# YTM32B1ME1 register map
Vendor: YTMicro; File version: 1.0
CPU: CM33 r0p4, little endian, MPU, FPU, 2 interrupt priority bits
Registers are 32-bit, read-write, reset 0x0 unless marked. A register's access mark holds for its fields unless they carry their own. Offsets are from the block's base; [hi:lo] are bit positions; {n}, {i} and the like mark numbered series; 'fields as' and 'values as' point back to an identical list; <NAME> marks a mode.

## SENT0 — Single Edge Nibble Transmission
Base 0x40160000; register names take the prefix SENT0_
0x00 CTRL
  [0] EN — Sent module enable control.
    0=Disabled; 1=Enabled
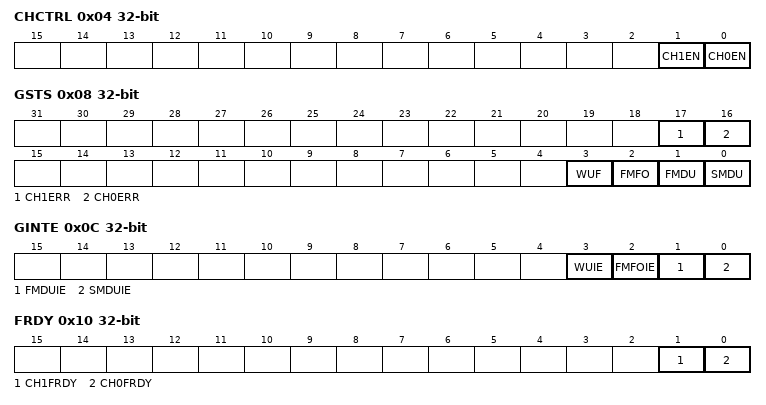
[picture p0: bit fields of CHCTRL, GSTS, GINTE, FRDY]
0x04 CHCTRL
  [1] CH1EN — Sent channel 1 enable control.
    0=Disabled; 1=Enabled
  [0] CH0EN — Sent channel 0 enable control.
    0=Disabled; 1=Enabled
0x08 GSTS
  [17] CH1ERR ro — Indicate channel 1 receive error status.
    0=No error detected; 1=Any error detected on channel 1
  [16] CH0ERR ro — Indicate channel 0 receive error status.
    0=No error detected; 1=Any error detected on channel 0
  [3] WUF — Indicate received valid data from PAD. This flag can be used to wake up chip from low power mode. Write 1 to clear this bit.
    0=No valid input was detected; 1=Valid input was detected
  [2] FMFO — Indicate fast message is received on any channel when FIFO is full. This bit is valid only when FIFO is enabled. Write 1 to clear this bit.
    0=No overflow; 1=Overflow occurred
  [1] FMDU — Indicate read when Fast Message DMA buffer or FIFO is empty. Write 1 to clear this bit.
    0=No underflow; 1=Underflow occurred
  [0] SMDU — Indicate read when Slow Serial Message DMA buffer is empty. Write 1 to clear this bit.
    0=No underflow; 1=Underflow occurred
0x0C GINTE
  [all] fields
    0=Disabled; 1=Enabled
  [3] WUIE — Wake-up interrupt enable control.
  [2] FMFOIE — Fast Message FIFO overflow interrupt enable control.
  [1] FMDUIE — Fast Message DMA buffer or FIFO underflow interrupt enable control.
  [0] SMDUIE — Slow Serial Message DMA buffer underflow interrupt enable control.
0x10 FRDY
  [1] CH1FRDY — Indicate channel 1 Fast Message receive ready.
    0=No Fast Message is available to be read out; 1=Fast Message is available to be read out
  [0] CH0FRDY — Indicate channel 0 Fast Message receive ready.
    values as CH1FRDY
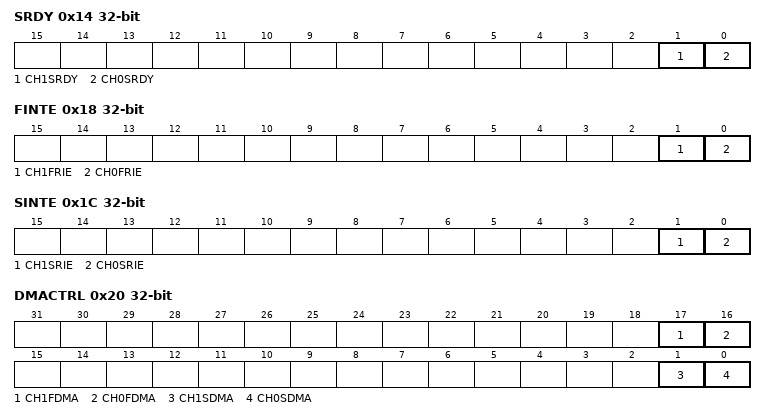
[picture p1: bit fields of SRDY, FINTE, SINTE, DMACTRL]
0x14 SRDY
  [1] CH1SRDY — Indicate channel 1 Slow Serial Message receive ready.
    0=No Slow Serial Message is available to be read out; 1=Slow Serial Message is available to be read out
  [0] CH0SRDY — Indicate channel 0 Slow Serial Message receive ready.
    values as CH1SRDY
0x18 FINTE
  [1] CH1FRIE — Channel 1 Fast Message ready interrupt enable control.
    0=Disabled; 1=Enable
  [0] CH0FRIE — Channel 0 Fast Message ready interrupt enable control.
    0=Disabled; 1=Enable
0x1C SINTE
  [1] CH1SRIE — Channel 1 Slow Serial Message ready interrupt enable control.
    0=Disabled; 1=Enabled
  [0] CH0SRIE — Channel 0 Slow Serial Message ready interrupt enable control.
    0=Disabled; 1=Enabled
0x20 DMACTRL
  [17] CH1FDMA — DMA enable control for Fast Message on channel 1.
    0=DMA for Fast Message is disabled; 1=DMA for Fast Message is enabled
  [16] CH0FDMA — DMA enable control for Fast Message on channel 0.
    values as CH1FDMA
  [1] CH1SDMA — DMA enable control for Slow Serial Message on channel 1.
    0=DMA for Slow Serial Message is disabled; 1=DMA for Slow Serial Message is enabled
  [0] CH0SDMA — DMA enable control for Slow Serial Message on channel 0.
    values as CH1SDMA
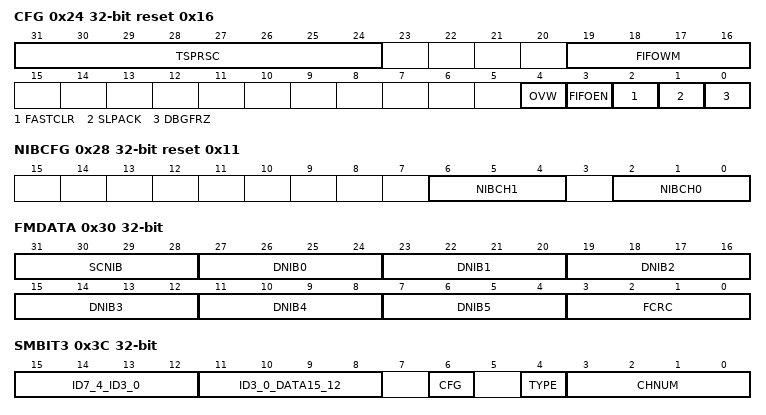
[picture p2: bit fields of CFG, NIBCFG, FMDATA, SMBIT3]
0x24 CFG reset 0x16
  [31:24] TSPRSC — Configure prescaler for internal time stamp clock. Time stamp clock = (Functional Clock)/(value+1).
  [19:16] FIFOWM — DMA read FIFO watermark level. Indicate the number of Fast Message to be stored in FIFO before a DMA request is asserted.
  [4] OVW — Select store mode of new data when FIFO is full. Discard new data or overwrite the old data with it.
    0=Overwrite is disabled, FIFO keeps old data, new data received will be discarded; 1=Overwrite is enabled, FIFO receives new data and overwrite the old data
  [3] FIFOEN — Internal FIFO enable control.
    0=FIFO disabled, Fast Message is read from buffer only; 1=FIFO enabled, Fast Message can be read from FIFO
  [2] FASTCLR — Fast clearing enable control. Enable clearing of ready status bits automatically when corresponding message is read.
    0=Fast clearing is disabled; 1=Fast clearing is enabled
  [1] SLPACK — Select acknowledge the low power mode request immediately or wait until internal state clean.
    0=Wait for several Functional Clock cycles until back to the idle state, then acknowledge the low power mode request; 1=Acknowledge the low power mode request immediately
  [0] DBGFRZ — Debug mode freeze control. Set this bit to disable module receiving under debug mode.
    0=Sent module stills work under debug mode; 1=Sent module is disabled under debug mode
0x28 NIBCFG reset 0x11
  [6:4] NIBCH1 — Number of data nibbles supported in channel 1.
  [2:0] NIBCH0 — Number of data nibbles supported in channel 0.
0x30 FMDATA ro — FIFO data output, DMA accesses register
  [31:28] SCNIB rw — Status and communication nibble of received Fast Message.
  [27-4n:24-4n] DNIB{n} rw (n=0..5) — Data {n} nibble of received Fast Message.
  [3:0] FCRC rw — 4-bit CRC of received Fast Message.
0x34 FMCHNUM ro — FIFO data output, DMA accesses register
  [3:0] CHNUM rw — Indicate the channel number of the received Fast Message.
0x38 FMTS ro — FIFO data output, DMA accesses register
  [31:0] TS rw — Indicate the time stamp of the received Fast Message.
0x3C SMBIT3 ro — DMA accesses register
  [15:12] ID7_4_ID3_0 rw — ID field. Value depends on 'C' bit. If 'C'=0, this field is ID[7:4]; If 'C'=1, this field is ID[3:0].
  [11:8] ID3_0_DATA15_12 rw — ID or Data field. Value depends on 'C' bit. If 'C'=0, this field is ID[3:0]; If 'C'=1, this field is DATA[15:12].
  [6] CFG rw — Configuration bit 'C'. Indicate the type of Enhances Serial Message.
    0=Enhanced Serial Message with 8-bit ID field; 1=Enhanced Serial Message with 4-bit ID field
  [4] TYPE rw — Serial message type. Indicate the type of received Slow Serial Message.
    0=Short Serial Message; 1=Enhanced Serial Message
  [3:0] CHNUM rw — Indicate the channel number of the received Slow Serial Message.
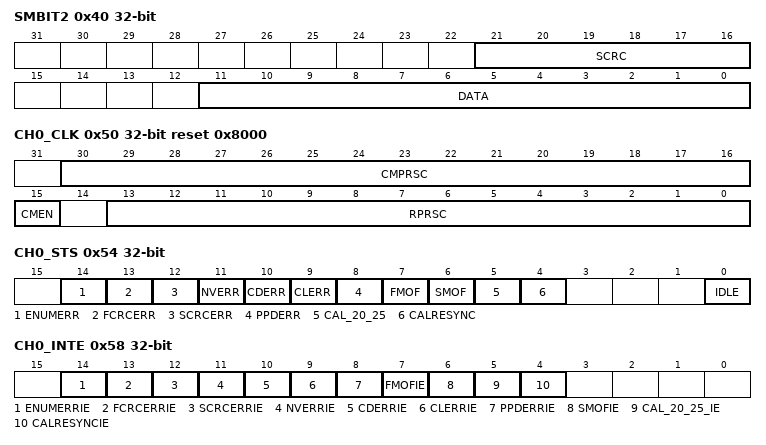
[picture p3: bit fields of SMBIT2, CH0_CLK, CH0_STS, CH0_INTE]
0x40 SMBIT2 ro — DMA accesses register
  [21:16] SCRC rw — CRC value of the Slow Serial Message. When TYPE=0, this CRC is 4-bit for Short Serial Message; When TYPE=1, this CRC is 6-bit for Enhanced Serial Message.
  [11:0] DATA rw
0x44 SMTS ro — DMA accesses register
  [31:0] TS rw — Indicate the time stamp of the received Slow Serial Message.
0x50 CH0_CLK reset 0x8000 — n=0,1,...
  [30:16] CMPRSC ro — This value is used to compensate the TX clock variation, it's calculated by internal clock compensation logic. ewline '= Receive Prescaler Value' No variation, no compensation or compensation is disabled. ewline '< Receive Prescaler Value' TX clock is faster than the programmed receive clock. ewline '> Receive Prescaler Value' TX clock is slower than the programmed receive clock.
  [15] CMEN — Compensation enable control.
    0=Compensation disabled; 1=Compensation enabled
  [13:0] RPRSC — This factor is used to generate required receive clock tick from the Functional Clock. It can only be written when channel enable bit is 0. Write 0 to bypass the prescaler, should not be used. RPRSC=(receive clock tick)/(functional clock period). It's suggested to choose a high frequency functional clock (>=12MHz) which can improve the reception accuracy.
0x54 CH0_STS — n=0,1,...
  [14] ENUMERR — Indicate the edge number error state. This error will only set when "Option 1" for successive calibration check is selected. Write 1 to clear this bit.
    0=No error detected; 1=Not the expected number of negative edges between calibration pulse
  [13] FCRCERR — Indicate checksum error in Fast Message. Write 1 to clear this bit.
    0=No error detected; 1=Not the expected CRC value of received Fast Message
  [12] SCRCERR — Indicate checksum error in Slow Serial Message. Write 1 to clear this bit.
    0=No error detected; 1=Not the expected CRC value of received Slow Serial Message
  [11] NVERR — Indicate nibble value error. Write 1 to clear this bit.
    0=No error detected; 1=Invalid nibble value that < 0 or > 15 detected
  [10] CDERR — Indicate error about successive calibration pulses differ. Write 1 to clear this bit.
    0=No error detected; 1=Successive calibration pulses differ by > +1.5625% or < -1.5625%
  [9] CLERR — Indicate calibration pulse length error. Write 1 to clear this bit.
    0=No error detected; 1=Calibration pulse is more than 56 ticks ±25%
  [8] PPDERR — Indicate the ratio of calibration pulse to overall message length error. This check is valid only for message with pause pulse. Write 1 to clear this bit.
    0=No error detected; 1=The ratio of calibration pulse length to overall message length (with pause pulse) is more than ±1.5625%
  [7] FMOF — Indicate Fast Message overflow occured on this channel. Write 1 to clear this bit.
    0=No error detected; 1=Overflow occured
  [6] SMOF — Indicate Slow Serial Message overflow occured on this channel. Write 1 to clear this bit.
    0=No error detected; 1=Overflow occured
  [5] CAL_20_25 — Indicate the calibration pulse variation information. Write 1 to clear this bit.
    0=Calibration pulse variation is less than 56 ticks ±20% or more than 56 ticks ±25%; 1=Calibration pulse variation is between ±20% to ±25% from 56 ticks
  [4] CALRESYNC — Indicate the resynchronized error. Write 1 to clear this bit.
    0=No error detected; 1=Successive calibration check has failed three times and assume 3rd message to be correct and will be received
  [0] IDLE ro — Indicate channel receive idle state.
    0=Channel is busy; 1=Channel is idle
0x58 CH0_INTE — n=0,1,...
  [all] fields
    0=Disabled; 1=Enabled
  [14] ENUMERRIE — Edge number error interrupt enable control.
  [13] FCRCERRIE — Fast Message checksum error interrupt enable control.
  [12] SCRCERRIE — Slow Serial Message checksum error interrupt enable control.
  [11] NVERRIE — Nibble value error interrupt enable control.
  [10] CDERRIE — Calibration diagnose error interrupt enable control.
  [9] CLERRIE — Calibration pulse length error interrupt enable control.
  [8] PPDERRIE — Pause pulse diagnose error interrupt enable control.
  [7] FMOFIE — Fast Message overflow interrupt enable control.
  [6] SMOFIE — Slow Serial Message overflow interrupt enable control.
  [5] CAL_20_25_IE — Calibration variation 20%-25% interrupt enable control.
  [4] CALRESYNCIE — Resynchronized error interrupt enable control.
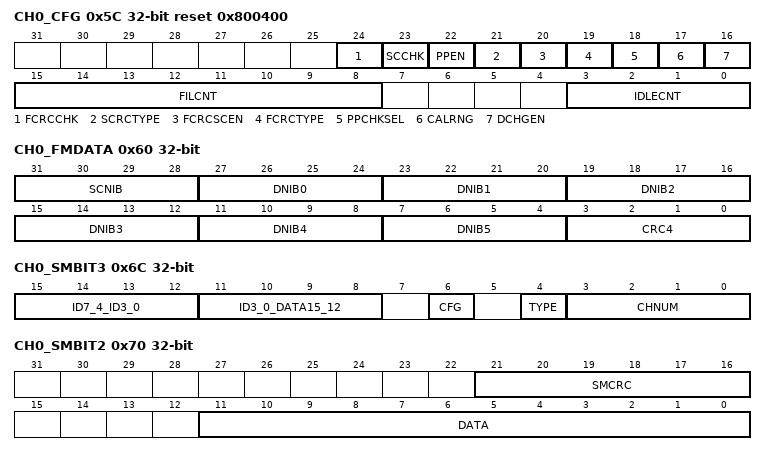
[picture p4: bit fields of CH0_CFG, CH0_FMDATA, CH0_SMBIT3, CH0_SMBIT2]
0x5C CH0_CFG reset 0x800400 — n=0,1,...
  [24] FCRCCHK — Control Fast Message CRC check on/off. If enable the check, Fast Message CRC error will break the current reception.
    0=Check is enabled; 1=Check is disabled
  [23] SCCHK — Select successive calibration check type.
    0=Select option 2 (Low Latency Option) as SAE Specification; 1=Select option 1 (Preferred but High Latency Option) as SAE Specification
  [22] PPEN — Pause pulse detection enable control.
    0=Detection of pause pulse is disabled; 1=Detection of pause pulse is enabled
  [21] SCRCTYPE — Select Slow Serial Message CRC check type.
    0=Recommended implementation (additional 0 data nibble XORed with the rest of the nibbles); 1=Legacy implementation (no additional 0 data nibble XORed)
  [20] FCRCSCEN — Select the status and communication nibble used for CRC calculation or not.
    0=Status and communication nibble not used for CRC calculation; 1=Status and communication nibble is used for CRC calculation
  [19] FCRCTYPE — Select Fast Message CRC check type.
    values as SCRCTYPE
  [18] PPCHKSEL — Select pause pulse check type.
    0=Both successive calibration pulse check and pause pulse diagnostic are run; 1=Only pause pulse diagnostic is run, successive calibration pulse check is disabled
  [17] CALRNG — Select calibration pulse range to be check.
    0=20% variation is acceptable; 1=25% variation is acceptable
  [16] DCHGEN — Select if only different Fast Message data can be stored into buffer and generate an interrupt or DMA request.
    0=All Fast Messages will be received even if data nibbles are same; 1=Only Fast Messages with different values of data nibbles will be received
  [15:8] FILCNT — Input filter sample count. Used to filter input glitch. Write non-zero value to enable the filter. Only the lowest non-zero bit is valid in this field.
    1=The input data is valid only when the keep time is larger than 2^1 functional clock cycles; 2=The input data is valid only when the keep time is larger than 2^2 functional clock cycles; 4=The input data is valid only when the keep time is larger than 2^3 functional clock cycles; 8=The input data is valid only when the keep time is larger than 2^4 functional clock cycles; 16=The input data is valid only when the keep time is larger than 2^5 functional clock cycles; 32=The input data is valid only when the keep time is larger than 2^6 functional clock cycles; 64=The input data is valid only when the keep time is larger than 2^7 functional clock cycles; 128=The input data is valid only when the keep time is larger than 2^8 functional clock cycles
  [3:0] IDLECNT — Bus idle count. Used to define the maximum allowable idle period on the sensor interface of this channel.
    0=Disabled; 1=127*2 receiver clock tick counts; 2=127*4 receiver clock tick counts; 4=127*8 receiver clock tick counts; 8=127*16 receiver clock tick counts
0x60 CH0_FMDATA ro — n=0,1,...
  [31:28] SCNIB rw — Status and communication nibble of received Fast Message.
  [27-4n:24-4n] DNIB{n} rw (n=0..5) — Data {n} nibble of received Fast Message.
  [3:0] CRC4 rw — 4-bit CRC of received Fast Message.
0x64 CH0_FMCHNUM ro — n=0,1,...
  fields as FMCHNUM
0x68 CH0_FMTS ro — n=0,1,...
  [31:0] TS rw — Indicate the time stamp of the received Fast Message.
0x6C CH0_SMBIT3 ro — n=0,1,...
  fields as SMBIT3
0x70 CH0_SMBIT2 ro — n=0,1,...
  [21:16] SMCRC rw — CRC value of the Slow Serial Message. When TYPE=0, this CRC is 4-bit for Short Serial Message; When TYPE=1, this CRC is 6-bit for Enhanced Serial Message.
  [11:0] DATA rw
0x74 CH0_SMTS ro — n=0,1,...
  fields as SMTS
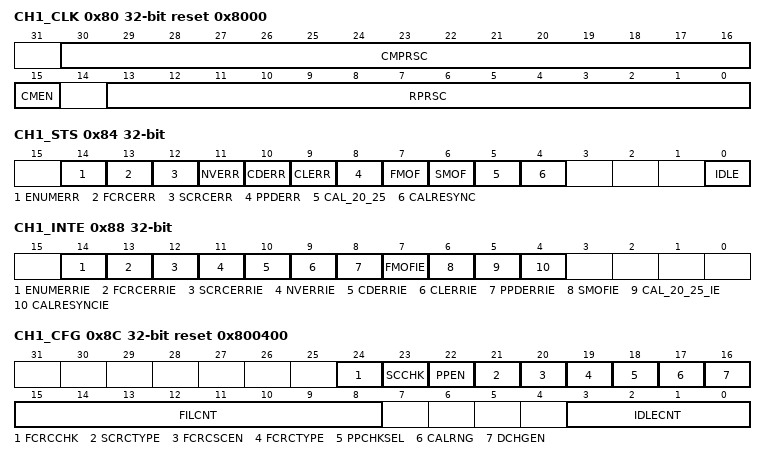
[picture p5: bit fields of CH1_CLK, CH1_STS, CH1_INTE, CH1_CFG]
0x80 CH1_CLK reset 0x8000 — n=0,1,...
  fields as CH0_CLK
0x84 CH1_STS — n=0,1,...
  fields as CH0_STS
0x88 CH1_INTE — n=0,1,...
  fields as CH0_INTE
0x8C CH1_CFG reset 0x800400 — n=0,1,...
  fields as CH0_CFG
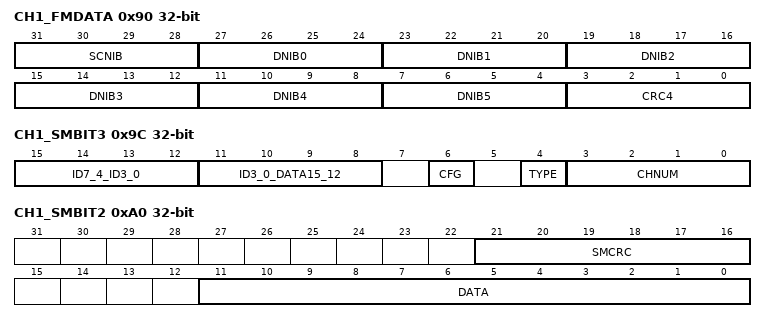
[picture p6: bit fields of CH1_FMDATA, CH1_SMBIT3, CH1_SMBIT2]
0x90 CH1_FMDATA ro — n=0,1,...
  fields as CH0_FMDATA
0x94 CH1_FMCHNUM ro — n=0,1,...
  fields as FMCHNUM
0x98 CH1_FMTS ro — n=0,1,...
  [31:0] TS rw — Indicate the time stamp of the received Fast Message.
0x9C CH1_SMBIT3 ro — n=0,1,...
  fields as SMBIT3
0xA0 CH1_SMBIT2 ro — n=0,1,...
  fields as CH0_SMBIT2
0xA4 CH1_SMTS ro — n=0,1,...
  fields as SMTS
